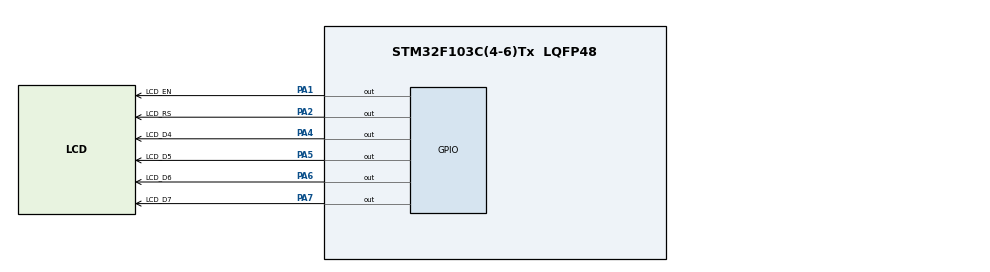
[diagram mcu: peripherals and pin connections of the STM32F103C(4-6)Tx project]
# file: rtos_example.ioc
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FREERTOS.Tasks01=defaultTask,24,128,StartDefaultTask,Default,NULL,Dynamic,NULL,NULL;LCD_Task,24,128,StartTaskLCD,Default,NULL,Dynamic,NULL,NULL
FREERTOS.configUSE_NEWLIB_REENTRANT=0
Mcu.Family=STM32F1
Mcu.Name=STM32F103C(4-6)Tx
Mcu.Package=LQFP48
NVIC.PriorityGroup=NVIC_PRIORITYGROUP_4
NVIC.TIM1_UP_IRQn=true\:15\:0\:false\:false\:true\:false\:false\:true\:true
NVIC.TimeBase=TIM1_UP_IRQn
NVIC.TimeBaseIP=TIM1
PA1.GPIO_Label=LCD_EN
PA1.Signal=GPIO_Output
PA2.GPIO_Label=LCD_RS
PA2.Signal=GPIO_Output
PA4.GPIO_Label=LCD_D4
PA4.Signal=GPIO_Output
PA5.GPIO_Label=LCD_D5
PA5.Signal=GPIO_Output
PA6.GPIO_Label=LCD_D6
PA6.Signal=GPIO_Output
PA7.GPIO_Label=LCD_D7
PA7.Signal=GPIO_Output
PD0-OSC_IN.Mode=HSE-External-Oscillator
PD0-OSC_IN.Signal=RCC_OSC_IN
PD1-OSC_OUT.Mode=HSE-External-Oscillator
PD1-OSC_OUT.Signal=RCC_OSC_OUT
ProjectManager.HeapSize=0x200
ProjectManager.StackSize=0x400
ProjectManager.TargetToolchain=MDK-ARM V5.32
RCC.APB1Freq_Value=8000000
RCC.APB2Freq_Value=8000000
VP_FREERTOS_VS_CMSIS_V2.Mode=CMSIS_V2
VP_SYS_VS_ND.Mode=No_Debug
VP_SYS_VS_tim1.Mode=TIM1
board=custom

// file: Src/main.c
/* USER CODE BEGIN Header */
/**
  ******************************************************************************
  * @file           : main.c
  * @brief          : Main program body
  ******************************************************************************
  * @attention
  *
  * Copyright (c) 2025 STMicroelectronics.
  * All rights reserved.
  *
  * This software is licensed under terms that can be found in the LICENSE file
  * in the root directory of this software component.
  * If no LICENSE file comes with this software, it is provided AS-IS.
  *
  ******************************************************************************
  */
/* USER CODE END Header */
#include "main.h"
#include "cmsis_os.h"

/* Definitions for defaultTask */
osThreadId_t defaultTaskHandle;
const osThreadAttr_t defaultTask_attributes = {
  .name = "defaultTask",
  .stack_size = 128 * 4,
  .priority = (osPriority_t) osPriorityNormal,
};
// Definitions for LCD_Task
osThreadId_t LCD_TaskHandle;
const osThreadAttr_t LCD_Task_attributes = {
  .name = "LCD_Task",
  .stack_size = 128 * 4,
  .priority = (osPriority_t) osPriorityNormal,
};

void SystemClock_Config(void);
static void MX_GPIO_Init(void);
void StartDefaultTask(void *argument);
void StartLCDTask(void *argument);  // Use this for LCD Task

/* USER CODE BEGIN PFP */
void MX_FREERTOS_Init(void) {
  /* Create the defaultTask (optionally keep or remove if not needed) */
  defaultTaskHandle = osThreadNew(StartDefaultTask, NULL, &defaultTask_attributes);

  /* Create the LCD Task */
  LCD_TaskHandle = osThreadNew(StartLCDTask, NULL, &LCD_Task_attributes);
}
/* USER CODE END PFP */

int main(void)
{

  /* MCU Configuration--------------------------------------------------------*/

  /* Reset of all peripherals, Initializes the Flash interface and the Systick. */
  HAL_Init();

  /* Configure the system clock */
  SystemClock_Config();

  /* Initialize all configured peripherals */
  MX_GPIO_Init();

  /* Init scheduler */
  osKernelInitialize();

  /* Create the thread(s) */
  /* creation of defaultTask */
//  defaultTaskHandle = osThreadNew(StartDefaultTask, NULL, &defaultTask_attributes);

//  /* creation of LCD_Task */
//  LCD_TaskHandle = osThreadNew(StartLCDTask, NULL, &LCD_Task_attributes);
	MX_FREERTOS_Init();

  /* Start scheduler */
  osKernelStart();

  /* We should never get here as control is now taken by the scheduler */

  /* Infinite loop */
  while (1)
  {

  }
}

void SystemClock_Config(void)
{
  RCC_OscInitTypeDef RCC_OscInitStruct = {0};
  RCC_ClkInitTypeDef RCC_ClkInitStruct = {0};

  /** Initializes the RCC Oscillators according to the specified parameters
  * in the RCC_OscInitTypeDef structure.
  */
  RCC_OscInitStruct.OscillatorType = RCC_OSCILLATORTYPE_HSI;
  RCC_OscInitStruct.HSIState = RCC_HSI_ON;
  RCC_OscInitStruct.HSICalibrationValue = RCC_HSICALIBRATION_DEFAULT;
  RCC_OscInitStruct.PLL.PLLState = RCC_PLL_NONE;
  if (HAL_RCC_OscConfig(&RCC_OscInitStruct) != HAL_OK)
  {
    Error_Handler();
  }

  /** Initializes the CPU, AHB and APB buses clocks
  */
  RCC_ClkInitStruct.ClockType = RCC_CLOCKTYPE_HCLK|RCC_CLOCKTYPE_SYSCLK
                              |RCC_CLOCKTYPE_PCLK1|RCC_CLOCKTYPE_PCLK2;
  RCC_ClkInitStruct.SYSCLKSource = RCC_SYSCLKSOURCE_HSI;
  RCC_ClkInitStruct.AHBCLKDivider = RCC_SYSCLK_DIV1;
  RCC_ClkInitStruct.APB1CLKDivider = RCC_HCLK_DIV1;
  RCC_ClkInitStruct.APB2CLKDivider = RCC_HCLK_DIV1;

  if (HAL_RCC_ClockConfig(&RCC_ClkInitStruct, FLASH_LATENCY_0) != HAL_OK)
  {
    Error_Handler();
  }
}

static void MX_GPIO_Init(void)
{
  GPIO_InitTypeDef GPIO_InitStruct = {0};

  /* GPIO Ports Clock Enable */
  __HAL_RCC_GPIOA_CLK_ENABLE();

  /*Configure GPIO pin Output Level */
  HAL_GPIO_WritePin(GPIOA, LCD_EN_Pin|LCD_RS_Pin|LCD_D4_Pin|LCD_D5_Pin
                          |LCD_D6_Pin|LCD_D7_Pin, GPIO_PIN_RESET);

  /*Configure GPIO pins : LCD_EN_Pin LCD_RS_Pin LCD_D4_Pin LCD_D5_Pin
                           LCD_D6_Pin LCD_D7_Pin */
  GPIO_InitStruct.Pin = LCD_EN_Pin|LCD_RS_Pin|LCD_D4_Pin|LCD_D5_Pin
                          |LCD_D6_Pin|LCD_D7_Pin;
  GPIO_InitStruct.Mode = GPIO_MODE_OUTPUT_PP;
  GPIO_InitStruct.Pull = GPIO_NOPULL;
  GPIO_InitStruct.Speed = GPIO_SPEED_FREQ_LOW;
  HAL_GPIO_Init(GPIOA, &GPIO_InitStruct);

}

void StartDefaultTask(void *argument)
{
  for(;;)
  {
    osDelay(1);
  }
}

void StartLCDTask(void *argument)
{
  // LCD code is in freertos.c
  extern void LCD_TaskBody(void *argument);
  LCD_TaskBody(argument);
}

void StartTask02(void *argument)
{
  for(;;)
  {
    osDelay(1);
  }
}

void HAL_TIM_PeriodElapsedCallback(TIM_HandleTypeDef *htim)
{
  if (htim->Instance == TIM1)
  {
    HAL_IncTick();
  }
}

void Error_Handler(void)
{
  __disable_irq();
  while (1)
  {
  }
}

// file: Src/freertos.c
/* USER CODE BEGIN Header */
/**
  ******************************************************************************
  * File Name          : freertos.c
  * Description        : Code for freertos applications
  ******************************************************************************
  * @attention
  *
  * Copyright (c) 2025 STMicroelectronics.
  * All rights reserved.
  *
  * This software is licensed under terms that can be found in the LICENSE file
  * in the root directory of this software component.
  * If no LICENSE file comes with this software, it is provided AS-IS.
  *
  ******************************************************************************
  */
/* USER CODE END Header */

#include "FreeRTOS.h"
#include "task.h"
#include "main.h"
#include "lcd.h"
#include "cmsis_os2.h"

/* USER CODE BEGIN Application */
void StartLCDTask(void *argument) {
    LCD_Init();
    LCD_Set_Cursor(0, 0);
    LCD_Send_String("Hello STM32!");
    LCD_Set_Cursor(1, 0);
    LCD_Send_String("FreeRTOS Ready");

    for (;;) {
        osDelay(1000);
    }
}

/* USER CODE END Application */
